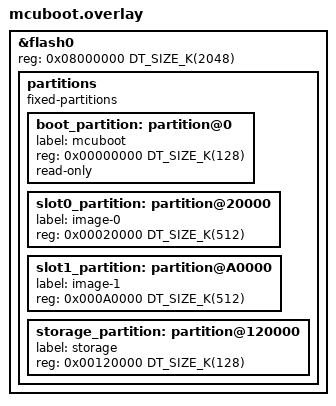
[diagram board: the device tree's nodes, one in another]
/*
 * Shared flash partition layout for MCUboot (2MB M7 flash @ 0x08000000).
 *
 * Remove ranges from flash0 to prevent DT_FIXED_PARTITION_ADDR from
 * double-adding the flash base address.
 *
 * SWAP_USING_OFFSET: first 128KB of slot1 is swap scratch;
 * image payload starts at slot1 offset 0x20000.
 */
&flash0 {
    /delete-property/ ranges;
    reg = <0x08000000 DT_SIZE_K(2048)>;

    partitions {
        compatible = "fixed-partitions";
        #address-cells = <1>;
        #size-cells = <1>;
        ranges;

        boot_partition: partition@0 {
            label = "mcuboot";
            reg = <0x00000000 DT_SIZE_K(128)>;
            read-only;
        };

        slot0_partition: partition@20000 {
            label = "image-0";
            reg = <0x00020000 DT_SIZE_K(512)>;
        };

        slot1_partition: partition@A0000 {
            label = "image-1";
            reg = <0x000A0000 DT_SIZE_K(512)>;
        };

        storage_partition: partition@120000 {
            label = "storage";
            reg = <0x00120000 DT_SIZE_K(128)>;
        };
    };
};
